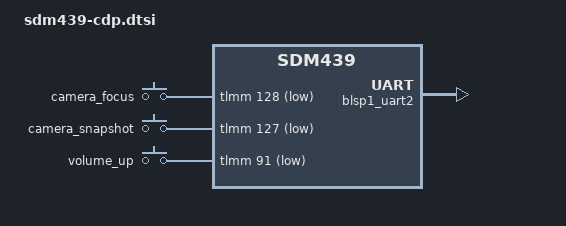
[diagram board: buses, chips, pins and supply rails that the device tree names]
/*
 * Copyright (c) 2018, The Linux Foundation. All rights reserved.
 *
 * This program is free software; you can redistribute it and/or modify
 * it under the terms of the GNU General Public License version 2 and
 * only version 2 as published by the Free Software Foundation.
 *
 * This program is distributed in the hope that it will be useful,
 * but WITHOUT ANY WARRANTY; without even the implied warranty of
 * MERCHANTABILITY or FITNESS FOR A PARTICULAR PURPOSE.  See the
 * GNU General Public License for more details.
 */

#include "sdm439-camera-sensor-cdp.dtsi"

&blsp1_uart2 {
	status = "ok";
};

&soc {
	gpio_keys {
		compatible = "gpio-keys";
		input-name = "gpio-keys";
		pinctrl-names = "default";
		pinctrl-0 = <&gpio_key_active>;

		camera_focus {
			label = "camera_focus";
			gpios = <&tlmm 128 0x1>;
			linux,input-type = <1>;
			linux,code = <0x210>;
			debounce-interval = <15>;
			linux,can-disable;
			gpio-key,wakeup;
		};

		camera_snapshot {
			label = "camera_snapshot";
			gpios = <&tlmm 127 0x1>;
			linux,input-type = <1>;
			linux,code = <0x2fe>;
			debounce-interval = <15>;
			linux,can-disable;
			gpio-key,wakeup;
		};

		vol_up {
			label = "volume_up";
			gpios = <&tlmm 91 0x1>;
			linux,input-type = <1>;
			linux,code = <115>;
			debounce-interval = <15>;
			linux,can-disable;
			gpio-key,wakeup;
		};
	};
};
